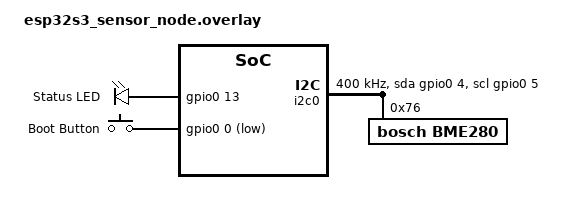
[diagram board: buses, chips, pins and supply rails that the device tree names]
/*
 * Vajra-Dhīr EDA — Zephyr RTOS Devicetree Overlay
 * Target: ESP32-S3 Sensor Node (VD-BRD-002)
 */

/ {
    aliases {
        led0 = &status_led;
        sw0 = &boot_button;
    };

    leds {
        compatible = "gpio-leds";
        status_led: led_0 {
            gpios = <&gpio0 13 GPIO_ACTIVE_HIGH>;
            label = "Status LED";
        };
    };

    buttons {
        compatible = "gpio-keys";
        boot_button: button_0 {
            gpios = <&gpio0 0 (GPIO_PULL_UP | GPIO_ACTIVE_LOW)>;
            label = "Boot Button";
        };
    };
};

&i2c0 {
    status = "okay";
    clock-frequency = <I2C_BITRATE_FAST>;
    sda-gpios = <&gpio0 4 (GPIO_PULL_UP | GPIO_OPEN_DRAIN)>;
    scl-gpios = <&gpio0 5 (GPIO_PULL_UP | GPIO_OPEN_DRAIN)>;

    bme280: bme280@76 {
        compatible = "bosch,bme280";
        reg = <0x76>;
        status = "okay";
    };
};
